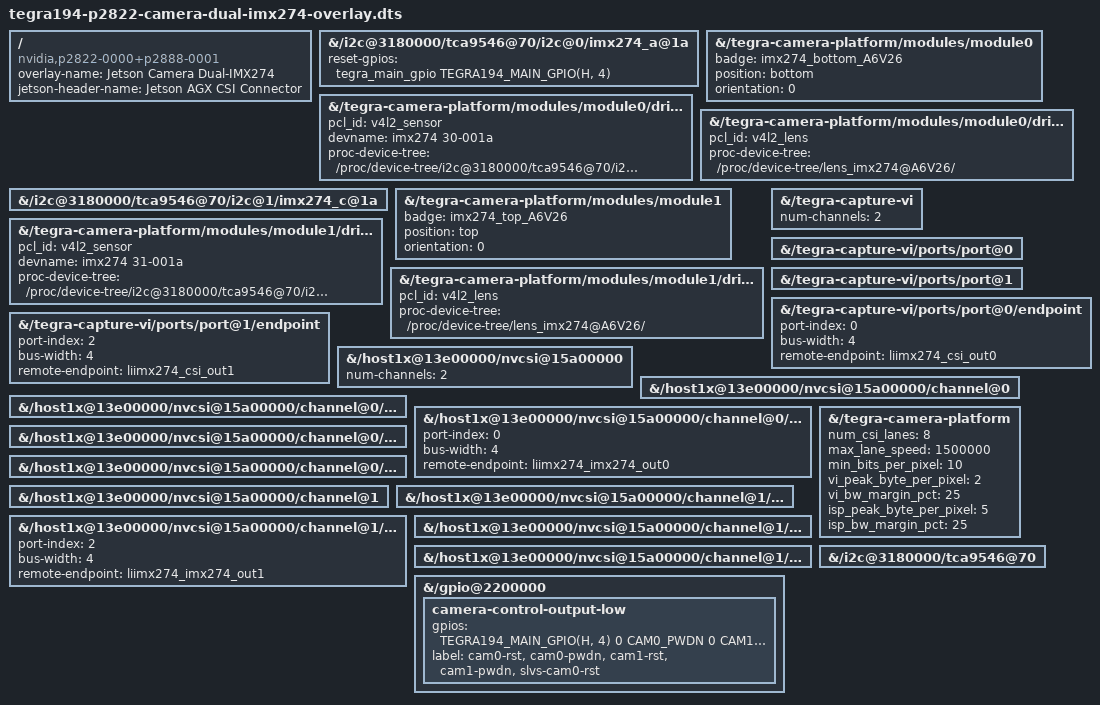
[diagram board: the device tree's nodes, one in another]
// SPDX-License-Identifier: GPL-2.0-only
/*
 * Jetson Device-tree overlay for Camera Dual-IMX274 on t19x platforms
 *
 * Copyright (c) 2022 NVIDIA CORPORATION. All rights reserved.
 *
 */

#include <dt-bindings/gpio/tegra194-gpio.h>

#define CAM0_RST_L      TEGRA194_MAIN_GPIO(H, 3)
#define CAM0_PWDN       TEGRA194_MAIN_GPIO(H, 6)
#define CAM1_RST_L      TEGRA194_MAIN_GPIO(T, 6)
#define CAM1_PWDN       TEGRA194_MAIN_GPIO(T, 5)
#define SLVS_CAM0_RST_L TEGRA194_MAIN_GPIO(Y, 1)

/dts-v1/;
/plugin/;

/ {
	overlay-name = "Jetson Camera Dual-IMX274";
	jetson-header-name = "Jetson AGX CSI Connector";
	compatible = "nvidia,p2822-0000+p2888-0001","nvidia,jetson-xavier-industrial";

	fragment@0 {
		target-path = "/i2c@3180000/tca9546@70/i2c@0/imx274_a@1a";
		board_config {
			odm-data = "enable-dual-imx274";
			sw-modules = "kernel";
		};
		__overlay__ {
			status = "okay";
		};
	};
	fragment@1 {
		target-path = "/tegra-camera-platform/modules/module0";
		board_config {
			odm-data = "enable-dual-imx274";
			sw-modules = "kernel";
		};
		__overlay__ {
			status = "okay";
			badge = "imx274_bottom_A6V26";
			position = "bottom";
			orientation = "0";
		};
	};
	fragment@2 {
		target-path = "/tegra-camera-platform/modules/module0/drivernode0";
		board_config {
			odm-data = "enable-dual-imx274";
			sw-modules = "kernel";
		};
		__overlay__ {
			status = "okay";
			pcl_id = "v4l2_sensor";
			devname = "imx274 30-001a";
			proc-device-tree = "/proc/device-tree/i2c@3180000/tca9546@70/i2c@0/imx274_a@1a";
		};
	};
	fragment@3 {
		target-path = "/tegra-camera-platform/modules/module0/drivernode1";
		board_config {
			odm-data = "enable-dual-imx274";
			sw-modules = "kernel";
		};
		__overlay__ {
			status = "okay";
			pcl_id = "v4l2_lens";
			proc-device-tree = "/proc/device-tree/lens_imx274@A6V26/";
		};
	};
	fragment@4 {
		target-path = "/i2c@3180000/tca9546@70/i2c@1/imx274_c@1a";
		board_config {
			odm-data = "enable-dual-imx274";
			sw-modules = "kernel";
		};
		__overlay__ {
			status = "okay";
		};
	};
	fragment@5 {
		target-path = "/tegra-camera-platform/modules/module1";
		board_config {
			odm-data = "enable-dual-imx274";
			sw-modules = "kernel";
		};
		__overlay__ {
			status = "okay";
			badge = "imx274_top_A6V26";
			position = "top";
			orientation = "0";
		};
	};
	fragment@6 {
		target-path = "/tegra-camera-platform/modules/module1/drivernode0";
		board_config {
			odm-data = "enable-dual-imx274";
			sw-modules = "kernel";
		};
		__overlay__ {
			status = "okay";
			pcl_id = "v4l2_sensor";
			devname = "imx274 31-001a";
			proc-device-tree = "/proc/device-tree/i2c@3180000/tca9546@70/i2c@1/imx274_c@1a";
		};
	};
	fragment@7 {
		target-path = "/tegra-camera-platform/modules/module1/drivernode1";
		board_config {
			odm-data = "enable-dual-imx274";
			sw-modules = "kernel";
		};
		__overlay__ {
			status = "okay";
			pcl_id = "v4l2_lens";
			proc-device-tree = "/proc/device-tree/lens_imx274@A6V26/";
		};
	};
	/* Enable VI ports - capture_vi_base, */
	fragment@8 {
		target-path = "/tegra-capture-vi";
		board_config {
			odm-data = "enable-dual-imx274";
			sw-modules = "kernel";
		};
		__overlay__ {
			num-channels=<2>;
		};
	};
	fragment@9 {
		target-path = "/tegra-capture-vi/ports/port@0";
		board_config {
			odm-data = "enable-dual-imx274";
			sw-modules = "kernel";
		};
		__overlay__ {
			status = "okay";
		};
	};
	fragment@10 {
		target-path = "/tegra-capture-vi/ports/port@1";
		board_config {
			odm-data = "enable-dual-imx274";
			sw-modules = "kernel";
		};
		__overlay__ {
			status = "okay";
		};
	};
	fragment@11 {
		target-path = "/tegra-capture-vi/ports/port@0/endpoint";
		board_config {
			odm-data = "enable-dual-imx274";
			sw-modules = "kernel";
		};
		__overlay__ {
			status = "okay";
			port-index = <0>;
			bus-width = <4>;
			remote-endpoint = "/host1x@13e00000/nvcsi@15a00000/channel@0/ports/port@1/endpoint@1";
		};
	};
	fragment@12 {
		target-path = "/tegra-capture-vi/ports/port@1/endpoint";
		board_config {
			odm-data = "enable-dual-imx274";
			sw-modules = "kernel";
		};
		__overlay__ {
			status = "okay";
			port-index = <2>;
			bus-width = <4>;
			remote-endpoint = "/host1x@13e00000/nvcsi@15a00000/channel@1/ports/port@1/endpoint@3";
		};
	};
	/* Enable CSI ports */
	fragment@13{
		target-path = "/host1x@13e00000/nvcsi@15a00000";
		board_config {
			odm-data = "enable-dual-imx274";
			sw-modules = "kernel";
		};
		__overlay__ {
			num-channels=<2>;
		};
	};
	fragment@14 {
		target-path = "/host1x@13e00000/nvcsi@15a00000/channel@0";
		board_config {
			odm-data = "enable-dual-imx274";
			sw-modules = "kernel";
		};
		__overlay__ {
			status = "okay";
		};
	};
	fragment@15 {
		target-path = "/host1x@13e00000/nvcsi@15a00000/channel@0/ports/port@0";
		board_config {
			odm-data = "enable-dual-imx274";
			sw-modules = "kernel";
		};
		__overlay__ {
			status = "okay";
		};
	};
	fragment@16 {
		target-path = "/host1x@13e00000/nvcsi@15a00000/channel@0/ports/port@0/endpoint@0";
		board_config {
			odm-data = "enable-dual-imx274";
			sw-modules = "kernel";
		};
		__overlay__ {
			status = "okay";
			port-index = <0>;
			bus-width = <4>;
			remote-endpoint = "/i2c@3180000/tca9546@70/i2c@0/imx274_a@1a/ports/port@0/endpoint";
		};
	};
	fragment@17 {
		target-path = "/host1x@13e00000/nvcsi@15a00000/channel@0/ports/port@1";
		board_config {
			odm-data = "enable-dual-imx274";
			sw-modules = "kernel";
		};
		__overlay__ {
			status = "okay";
		};
	};
	fragment@18 {
		target-path = "/host1x@13e00000/nvcsi@15a00000/channel@0/ports/port@1/endpoint@1";
		board_config {
			odm-data = "enable-dual-imx274";
			sw-modules = "kernel";
		};
		__overlay__ {
			status = "okay";
		};
	};
	fragment@19 {
		target-path = "/host1x@13e00000/nvcsi@15a00000/channel@1";
		board_config {
			odm-data = "enable-dual-imx274";
			sw-modules = "kernel";
		};
		__overlay__ {
			status = "okay";
		};
	};
	fragment@20 {
		target-path = "/host1x@13e00000/nvcsi@15a00000/channel@1/ports/port@0";
		board_config {
			odm-data = "enable-dual-imx274";
			sw-modules = "kernel";
		};
		__overlay__ {
			status = "okay";
		};
	};
	fragment@21 {
		target-path = "/host1x@13e00000/nvcsi@15a00000/channel@1/ports/port@0/endpoint@2";
		board_config {
			odm-data = "enable-dual-imx274";
			sw-modules = "kernel";
		};
		__overlay__ {
			status = "okay";
			port-index = <2>;
			bus-width = <4>;
			remote-endpoint = "/i2c@3180000/tca9546@70/i2c@1/imx274_c@1a/ports/port@0/endpoint";
		};
	};
	fragment@22 {
		target-path = "/host1x@13e00000/nvcsi@15a00000/channel@1/ports/port@1";
		board_config {
			odm-data = "enable-dual-imx274";
			sw-modules = "kernel";
		};
		__overlay__ {
			status = "okay";
		};
	};
	fragment@23 {
		target-path = "/host1x@13e00000/nvcsi@15a00000/channel@1/ports/port@1/endpoint@3";
		board_config {
			odm-data = "enable-dual-imx274";
			sw-modules = "kernel";
		};
		__overlay__ {
			status = "okay";
		};
	};
	/* tegra-camera-platform settings */
	fragment@24 {
		target-path = "/tegra-camera-platform";
		board_config {
			odm-data = "enable-dual-imx274";
			sw-modules = "kernel";
		};
		__overlay__ {
			num_csi_lanes = <8>;
			max_lane_speed = <1500000>;
			min_bits_per_pixel = <10>;
			vi_peak_byte_per_pixel = <2>;
			vi_bw_margin_pct = <25>;
			isp_peak_byte_per_pixel = <5>;
			isp_bw_margin_pct = <25>;
		};
	};
	/* pca9646 i2c mux */
	fragment@25 {
		target-path = "/i2c@3180000/tca9546@70";
		board_config {
			odm-data = "enable-dual-imx274";
			sw-modules = "kernel";
		};
		__overlay__ {
			status = "okay";
		};
	};

/////////////////////////////////////////////////////////////


	fragment@26 {
		target-path = "/i2c@3180000/tca9546@70/i2c@0/imx274_a@1a";
		board_config {
			ids = "LPRD-dual-imx274-002";
			sw-modules = "kernel";
		};
		__overlay__ {
			status = "okay";
		};
	};
	fragment@27 {
		target-path = "/tegra-camera-platform/modules/module0";
		board_config {
			ids = "LPRD-dual-imx274-002";
			sw-modules = "kernel";
		};
		__overlay__ {
			status = "okay";
			badge = "imx274_bottom_A6V26";
			position = "bottom";
			orientation = "0";
		};
	};
	fragment@28 {
		target-path = "/tegra-camera-platform/modules/module0/drivernode0";
		board_config {
			ids = "LPRD-dual-imx274-002";
			sw-modules = "kernel";
		};
		__overlay__ {
			status = "okay";
			pcl_id = "v4l2_sensor";
			devname = "imx274 30-001a";
			proc-device-tree = "/proc/device-tree/i2c@3180000/tca9546@70/i2c@0/imx274_a@1a";
		};
	};
	fragment@29 {
		target-path = "/tegra-camera-platform/modules/module0/drivernode1";
		board_config {
			ids = "LPRD-dual-imx274-002";
			sw-modules = "kernel";
		};
		__overlay__ {
			status = "okay";
			pcl_id = "v4l2_lens";
			proc-device-tree = "/proc/device-tree/lens_imx274@A6V26/";
		};
	};
	fragment@30 {
		target-path = "/i2c@3180000/tca9546@70/i2c@1/imx274_c@1a";
		board_config {
			ids = "LPRD-dual-imx274-002";
			sw-modules = "kernel";
		};
		__overlay__ {
			status = "okay";
		};
	};
	fragment@31 {
		target-path = "/tegra-camera-platform/modules/module1";
		board_config {
			ids = "LPRD-dual-imx274-002";
			sw-modules = "kernel";
		};
		__overlay__ {
			status = "okay";
			badge = "imx274_top_A6V26";
			position = "top";
			orientation = "0";
		};
	};
	fragment@32 {
		target-path = "/tegra-camera-platform/modules/module1/drivernode0";
		board_config {
			ids = "LPRD-dual-imx274-002";
			sw-modules = "kernel";
		};
		__overlay__ {
			status = "okay";
			pcl_id = "v4l2_sensor";
			devname = "imx274 31-001a";
			proc-device-tree = "/proc/device-tree/i2c@3180000/tca9546@70/i2c@1/imx274_c@1a";
		};
	};
	fragment@33 {
		target-path = "/tegra-camera-platform/modules/module1/drivernode1";
		board_config {
			ids = "LPRD-dual-imx274-002";
			sw-modules = "kernel";
		};
		__overlay__ {
			status = "okay";
			pcl_id = "v4l2_lens";
			proc-device-tree = "/proc/device-tree/lens_imx274@A6V26/";
		};
	};
	/* Enable VI ports - capture_vi_base, */
	fragment@34 {
		target-path = "/tegra-capture-vi";
		board_config {
			ids = "LPRD-dual-imx274-002";
			sw-modules = "kernel";
		};
		__overlay__ {
			num-channels=<2>;
		};
	};
	fragment@35 {
		target-path = "/tegra-capture-vi/ports/port@0";
		board_config {
			ids = "LPRD-dual-imx274-002";
			sw-modules = "kernel";
		};
		__overlay__ {
			status = "okay";
		};
	};
	fragment@36 {
		target-path = "/tegra-capture-vi/ports/port@1";
		board_config {
			ids = "LPRD-dual-imx274-002";
			sw-modules = "kernel";
		};
		__overlay__ {
			status = "okay";
		};
	};
	fragment@37 {
		target-path = "/tegra-capture-vi/ports/port@0/endpoint";
		board_config {
			ids = "LPRD-dual-imx274-002";
			sw-modules = "kernel";
		};
		__overlay__ {
			status = "okay";
			port-index = <0>;
			bus-width = <4>;
			/// remote-endpoint = "/host1x@13e00000/nvcsi@15a00000/channel@0/ports/port@1/endpoint@1";
			remote-endpoint = <&liimx274_csi_out0>;

		};
	};
	fragment@38 {
		target-path = "/tegra-capture-vi/ports/port@1/endpoint";
		board_config {
			ids = "LPRD-dual-imx274-002";
			sw-modules = "kernel";
		};
		__overlay__ {
			status = "okay";
			port-index = <2>;
			bus-width = <4>;
			/// remote-endpoint = "/host1x@13e00000/nvcsi@15a00000/channel@1/ports/port@1/endpoint@3";
			remote-endpoint = <&liimx274_csi_out1>;
		};
	};
	/* Enable CSI ports */
	fragment@39{
		target-path = "/host1x@13e00000/nvcsi@15a00000";
		board_config {
			ids = "LPRD-dual-imx274-002";
			sw-modules = "kernel";
		};
		__overlay__ {
			num-channels=<2>;
		};
	};
	fragment@40 {
		target-path = "/host1x@13e00000/nvcsi@15a00000/channel@0";
		board_config {
			ids = "LPRD-dual-imx274-002";
			sw-modules = "kernel";
		};
		__overlay__ {
			status = "okay";
		};
	};
	fragment@41 {
		target-path = "/host1x@13e00000/nvcsi@15a00000/channel@0/ports/port@0";
		board_config {
			ids = "LPRD-dual-imx274-002";
			sw-modules = "kernel";
		};
		__overlay__ {
			status = "okay";
		};
	};
	fragment@42 {
		target-path = "/host1x@13e00000/nvcsi@15a00000/channel@0/ports/port@0/endpoint@0";
		board_config {
			ids = "LPRD-dual-imx274-002";
			sw-modules = "kernel";
		};
		__overlay__ {
			status = "okay";
			port-index = <0>;
			bus-width = <4>;
			/// remote-endpoint = "/i2c@3180000/tca9546@70/i2c@0/imx274_a@1a/ports/port@0/endpoint";
			remote-endpoint = <&liimx274_imx274_out0>;
		};
	};
	fragment@43 {
		target-path = "/host1x@13e00000/nvcsi@15a00000/channel@0/ports/port@1";
		board_config {
			ids = "LPRD-dual-imx274-002";
			sw-modules = "kernel";
		};
		__overlay__ {
			status = "okay";
		};
	};
	fragment@44 {
		target-path = "/host1x@13e00000/nvcsi@15a00000/channel@0/ports/port@1/endpoint@1";
		board_config {
			ids = "LPRD-dual-imx274-002";
			sw-modules = "kernel";
		};
		__overlay__ {
			status = "okay";
		};
	};
	fragment@45 {
		target-path = "/host1x@13e00000/nvcsi@15a00000/channel@1";
		board_config {
			ids = "LPRD-dual-imx274-002";
			sw-modules = "kernel";
		};
		__overlay__ {
			status = "okay";
		};
	};
	fragment@46 {
		target-path = "/host1x@13e00000/nvcsi@15a00000/channel@1/ports/port@0";
		board_config {
			ids = "LPRD-dual-imx274-002";
			sw-modules = "kernel";
		};
		__overlay__ {
			status = "okay";
		};
	};
	fragment@47 {
		target-path = "/host1x@13e00000/nvcsi@15a00000/channel@1/ports/port@0/endpoint@2";
		board_config {
			ids = "LPRD-dual-imx274-002";
			sw-modules = "kernel";
		};
		__overlay__ {
			status = "okay";
			port-index = <2>;
			bus-width = <4>;
			/// remote-endpoint = "/i2c@3180000/tca9546@70/i2c@1/imx274_c@1a/ports/port@0/endpoint";
			remote-endpoint = <&liimx274_imx274_out1>;
		};
	};
	fragment@48 {
		target-path = "/host1x@13e00000/nvcsi@15a00000/channel@1/ports/port@1";
		board_config {
			ids = "LPRD-dual-imx274-002";
			sw-modules = "kernel";
		};
		__overlay__ {
			status = "okay";
		};
	};
	fragment@49 {
		target-path = "/host1x@13e00000/nvcsi@15a00000/channel@1/ports/port@1/endpoint@3";
		board_config {
			ids = "LPRD-dual-imx274-002";
			sw-modules = "kernel";
		};
		__overlay__ {
			status = "okay";
		};
	};
	/* tegra-camera-platform settings */
	fragment@50 {
		target-path = "/tegra-camera-platform";
		board_config {
			ids = "LPRD-dual-imx274-002";
			sw-modules = "kernel";
		};
		__overlay__ {
			num_csi_lanes = <8>;
			max_lane_speed = <1500000>;
			min_bits_per_pixel = <10>;
			vi_peak_byte_per_pixel = <2>;
			vi_bw_margin_pct = <25>;
			isp_peak_byte_per_pixel = <5>;
			isp_bw_margin_pct = <25>;
		};
	};
	/* pca9646 i2c mux */
	fragment@51 {
		target-path = "/i2c@3180000/tca9546@70";
		board_config {
			ids = "LPRD-dual-imx274-002";
			sw-modules = "kernel";
		};
		__overlay__ {
			status = "okay";
		};
	};

	/* fix cam0_rst gpio pin for older Galen boards */
	/* below GPIO overlays must be after all sensor board overlays */

	fragment@52 {
		target-path = "/gpio@2200000";
		board_config {
			ids = "<2822-0000-500";
			sw-modules = "kernel";
		};
		__overlay__ {
			camera-control-output-low {
				gpios = <TEGRA194_MAIN_GPIO(H, 4) 0 CAM0_PWDN 0
					CAM1_RST_L 0 CAM1_PWDN 0
					SLVS_CAM0_RST_L 0>;
				label = "cam0-rst", "cam0-pwdn",
					"cam1-rst", "cam1-pwdn",
					"slvs-cam0-rst";
				};
		};
	};
	fragment@53 {
		target-path = "/i2c@3180000/tca9546@70/i2c@0/imx274_a@1a";
		board_config {
			ids = "<2822-0000-500";
			sw-modules = "kernel";
		};
		__overlay__ {
			reset-gpios = <&tegra_main_gpio TEGRA194_MAIN_GPIO(H, 4) 0>;
		};
	};

};
